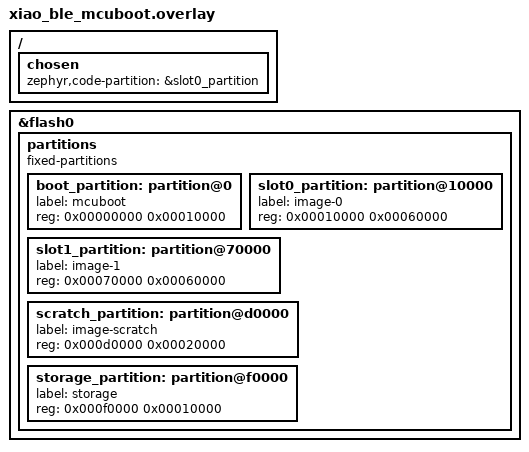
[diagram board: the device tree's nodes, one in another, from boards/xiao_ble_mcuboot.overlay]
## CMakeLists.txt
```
# SPDX-License-Identifier: Apache-2.0

cmake_minimum_required(VERSION 3.20.0)

find_package(Zephyr REQUIRED HINTS $ENV{ZEPHYR_BASE})
project(blinky)

target_sources(app PRIVATE src/main.c)

# Set the signing key for MCUboot
set(mcuboot_key_file "${CMAKE_CURRENT_SOURCE_DIR}/keys/mcuboot-rsa-key.pem")
set_property(GLOBAL PROPERTY PROPERTY_MCUBOOT_SIGNATURE_KEY_FILE "${mcuboot_key_file}")

# Configure OpenOCD runner for west flash
board_runner_args(openocd "--config=openocd-pico-nrf52.cfg")
```

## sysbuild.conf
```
# Sysbuild configuration for MCUboot
SB_CONFIG_BOOTLOADER_MCUBOOT=y
```

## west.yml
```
runner:
  openocd:
    args: ["-f", "openocd-pico-nrf52.cfg"]
```

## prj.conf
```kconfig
# SPDX-License-Identifier: Apache-2.0

# Enable GPIO
CONFIG_GPIO=y

# Enable LED support
CONFIG_LED=y

# Logging configuration
CONFIG_LOG=y
CONFIG_LOG_DEFAULT_LEVEL=3

# USB configuration
CONFIG_USB_DEVICE_STACK=y
CONFIG_USB_DEVICE_PRODUCT="Zephyr Data Streamer"
CONFIG_USB_CDC_ACM=y
CONFIG_USB_DEVICE_INITIALIZE_AT_BOOT=y

# CONFIG_USB_DEVICE_STACK_NEXT=y
# CONFIG_USBD_SHELL=y
# CONFIG_USBH_SHELL=y
# CONFIG_USB_DFU_CLASS=y


CONFIG_USB_DEVICE_STACK=y
#CONFIG_SHELL_BACKEND_USB=y

# Networking support (for external Wi-Fi modules)
CONFIG_NETWORKING=y
CONFIG_NET_TCP=y
CONFIG_NET_UDP=y
CONFIG_NET_IPV4=y
CONFIG_NET_DHCPV4=y
CONFIG_NET_SOCKETS=y
CONFIG_NET_SOCKETS_POSIX_NAMES=y

# MCUboot support for DFU
CONFIG_BOOTLOADER_MCUBOOT=y
CONFIG_MCUBOOT_SIGNATURE_KEY_FILE="keys/mcuboot-rsa-key.pem"
CONFIG_USB_CDC_ACM_LOG_LEVEL_DBG=n

# Console configuration - route to USB
CONFIG_CONSOLE=y
CONFIG_UART_CONSOLE=y

# Shell configuration
CONFIG_SHELL=y
CONFIG_SHELL_BACKEND_SERIAL=y
CONFIG_SHELL_BACKEND_RTT=y
CONFIG_SHELL_PROMPT_UART="usb:~$ "
CONFIG_SHELL_CMDS=y
CONFIG_SHELL_CMDS_RESIZE=y
CONFIG_KERNEL_SHELL=y
CONFIG_DEVICE_SHELL=y
CONFIG_LOG_DEFAULT_LEVEL=3
CONFIG_SHELL_LOG_BACKEND=y

# System reboot support
# CONFIG_REBOOT=y

# Bluetooth LE configuration for data streaming
CONFIG_BT=y
CONFIG_BT_SHELL=y
CONFIG_BT_PERIPHERAL=y
CONFIG_BT_DEVICE_NAME_DYNAMIC=y
CONFIG_BT_DEVICE_NAME="AlexBlue"
CONFIG_BT_DEVICE_APPEARANCE=0
CONFIG_BT_MAX_CONN=1
CONFIG_BT_L2CAP_TX_MTU=247
CONFIG_BT_BUF_ACL_TX_SIZE=251
CONFIG_BT_BUF_ACL_RX_SIZE=251
CONFIG_BT_HCI=y
CONFIG_BT_CTLR=y

# GATT service for custom data streaming
CONFIG_BT_GATT_SERVICE_CHANGED=y
CONFIG_BT_GATT_CACHING=y
```

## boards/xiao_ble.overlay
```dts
/*
 * Copyright (c) 2024
 * SPDX-License-Identifier: Apache-2.0
 */

/ {
	chosen {
		zephyr,code-partition = &slot0_partition;
	};
};

/* Delete the existing partition layout */
/delete-node/ &{/soc/flash-controller@4001e000/flash@0/partitions};

&flash0 {
	partitions {
		compatible = "fixed-partitions";
		#address-cells = <1>;
		#size-cells = <1>;

		/* Reserve space for MCUboot */
		mcuboot_partition: partition@0 {
			label = "mcuboot";
			reg = <0x000000000 0x0000C000>;
		};
		
		/* Main application slot */
		slot0_partition: partition@c000 {
			label = "image-0";
			reg = <0x0000C000 0x00076000>;
		};
		
		/* Update slot for DFU */
		slot1_partition: partition@82000 {
			label = "image-1";
			reg = <0x00082000 0x00076000>;
		};
		
		/* Storage area */
		storage_partition: partition@f8000 {
			label = "storage";
			reg = <0x000f8000 0x00008000>;
		};
	};
};
```

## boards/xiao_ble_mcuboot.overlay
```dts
// MCUboot device tree overlay for nRF52840
/delete-node/ &sd_partition;
/delete-node/ &code_partition;
/delete-node/ &storage_partition;
/delete-node/ &boot_partition;

/ {
	chosen {
		zephyr,code-partition = &slot0_partition;
	};
};

&flash0 {
	partitions {
		compatible = "fixed-partitions";
		#address-cells = <1>;
		#size-cells = <1>;

		boot_partition: partition@0 {
			label = "mcuboot";
			reg = <0x00000000 0x00010000>;
		};
		slot0_partition: partition@10000 {
			label = "image-0";
			reg = <0x00010000 0x00060000>;
		};
		slot1_partition: partition@70000 {
			label = "image-1";
			reg = <0x00070000 0x00060000>;
		};
		scratch_partition: partition@d0000 {
			label = "image-scratch";
			reg = <0x000d0000 0x00020000>;
		};
		storage_partition: partition@f0000 {
			label = "storage";
			reg = <0x000f0000 0x00010000>;
		};
	};
};
```

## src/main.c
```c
/*
 * Copyright (c) 2016 Intel Corporation
 *
 * SPDX-License-Identifier: Apache-2.0
 */

#include <zephyr/kernel.h>
#include <zephyr/drivers/gpio.h>
#include <zephyr/logging/log.h>
#include <zephyr/shell/shell.h>
#include <zephyr/sys/reboot.h>
#include <zephyr/bluetooth/bluetooth.h>
#include <zephyr/bluetooth/gap.h>
#include <zephyr/bluetooth/gatt.h>
#include <zephyr/bluetooth/uuid.h>

LOG_MODULE_REGISTER(main);

/* 1000 msec = 1 sec */
#define SLEEP_TIME_MS   1000

/* The devicetree node identifier for the "led0" alias. */
#define LED0_NODE DT_ALIAS(led0)

/*
 * A build error on this line means your board is unsupported.
 * See the sample documentation for information on how to fix this.
 */
static const struct gpio_dt_spec led = GPIO_DT_SPEC_GET(LED0_NODE, gpios);

/* Bluetooth advertising data */
static const struct bt_data ad[] = {
	BT_DATA_BYTES(BT_DATA_FLAGS, (BT_LE_AD_GENERAL | BT_LE_AD_NO_BREDR)),
	BT_DATA(BT_DATA_NAME_COMPLETE, CONFIG_BT_DEVICE_NAME, sizeof(CONFIG_BT_DEVICE_NAME) - 1),
};

/* Bluetooth scan response data (optional additional info) */
static const struct bt_data sd[] = {
	BT_DATA_BYTES(BT_DATA_UUID16_ALL, BT_UUID_16_ENCODE(BT_UUID_GATT_VAL)),
};

/* Bluetooth ready callback */
static void bt_ready_cb(int err)
{
	if (err) {
		LOG_ERR("Bluetooth init failed (err %d)", err);
		return;
	}

	LOG_INF("Bluetooth initialized");
	printk("Bluetooth initialized successfully\n");

	/* Start advertising */
	err = bt_le_adv_start(BT_LE_ADV_CONN_NAME, ad, ARRAY_SIZE(ad), sd, ARRAY_SIZE(sd));
	if (err) {
		LOG_ERR("Advertising failed to start (err %d)", err);
		printk("ERROR: Failed to start advertising! err = %d\n", err);
		return;
	}

	LOG_INF("Advertising successfully started");
	printk("Bluetooth advertising started as '%s'\n", CONFIG_BT_DEVICE_NAME);
}

/* Shell command to control LED */
static int cmd_led_on(const struct shell *shell, size_t argc, char **argv)
{
	ARG_UNUSED(argc);
	ARG_UNUSED(argv);
	
	gpio_pin_set_dt(&led, 1);
	shell_print(shell, "LED turned ON");
	return 0;
}

static int cmd_led_off(const struct shell *shell, size_t argc, char **argv)
{
	ARG_UNUSED(argc);
	ARG_UNUSED(argv);
	
	gpio_pin_set_dt(&led, 0);
	shell_print(shell, "LED turned OFF");
	return 0;
}

static int cmd_led_toggle(const struct shell *shell, size_t argc, char **argv)
{
	ARG_UNUSED(argc);
	ARG_UNUSED(argv);
	
	gpio_pin_toggle_dt(&led);
	shell_print(shell, "LED toggled");
	return 0;
}

static int cmd_dfu_mode(const struct shell *shell, size_t argc, char **argv)
{
	ARG_UNUSED(argc);
	ARG_UNUSED(argv);
	
	shell_print(shell, "Entering DFU mode...");
	shell_print(shell, "Device will reboot into bootloader for USB flashing");
	k_msleep(100); // Give time for message to be sent
	
	/* Reboot into DFU mode */
	// sys_reboot(SYS_REBOOT_COLD);
	
	return 0;
}

static int cmd_bt_start_adv(const struct shell *shell, size_t argc, char **argv)
{
	ARG_UNUSED(argc);
	ARG_UNUSED(argv);
	
	int err = bt_le_adv_start(BT_LE_ADV_CONN_NAME, ad, ARRAY_SIZE(ad), sd, ARRAY_SIZE(sd));
	if (err) {
		shell_print(shell, "Failed to start advertising (err %d)", err);
	} else {
		shell_print(shell, "Advertising started as '%s'", CONFIG_BT_DEVICE_NAME);
	}
	return 0;
}

static int cmd_bt_stop_adv(const struct shell *shell, size_t argc, char **argv)
{
	ARG_UNUSED(argc);
	ARG_UNUSED(argv);
	
	int err = bt_le_adv_stop();
	if (err) {
		shell_print(shell, "Failed to stop advertising (err %d)", err);
	} else {
		shell_print(shell, "Advertising stopped");
	}
	return 0;
}

SHELL_STATIC_SUBCMD_SET_CREATE(sub_led,
	SHELL_CMD(on, NULL, "Turn LED on", cmd_led_on),
	SHELL_CMD(off, NULL, "Turn LED off", cmd_led_off),
	SHELL_CMD(toggle, NULL, "Toggle LED", cmd_led_toggle),
	SHELL_SUBCMD_SET_END /* Array terminated. */
);

// SHELL_STATIC_SUBCMD_SET_CREATE(sub_bt,
//     SHELL_CMD(start, NULL, "Start advertising", cmd_bt_start_adv),
//     SHELL_CMD(stop, NULL, "Stop advertising", cmd_bt_stop_adv),
//     SHELL_SUBCMD_SET_END /* Array terminated. */
// );

SHELL_CMD_REGISTER(led, &sub_led, "LED commands", NULL);
// SHELL_CMD_REGISTER(bt, &sub_bt, "Bluetooth commands", NULL);
SHELL_CMD_REGISTER(dfu, NULL, "Enter DFU mode for USB flashing", cmd_dfu_mode);

int main(void)
{
	int ret;

	printk("=== nRF52840 Blinky Application Starting ===\n");

	if (!gpio_is_ready_dt(&led)) {
		LOG_ERR("Error: the LED devicetree node is not ready");
		printk("ERROR: LED devicetree node not ready!\n");
		return 0;
	}

	printk("LED GPIO is ready\n");

	ret = gpio_pin_configure_dt(&led, GPIO_OUTPUT_ACTIVE);
	if (ret < 0) {
		LOG_ERR("Error %d: failed to configure the LED pin", ret);
		printk("ERROR: Failed to configure LED pin! ret = %d\n", ret);
		return 0;
	}

	printk("LED pin configured successfully\n");

	/* Initialize Bluetooth */
	ret = bt_enable(bt_ready_cb);
	if (ret) {
		LOG_ERR("Bluetooth init failed (err %d)", ret);
		printk("ERROR: Bluetooth initialization failed! ret = %d\n", ret);
	} else {
		printk("Bluetooth initialization started...\n");
	}

	LOG_INF("LED blink example started");
	printk("Hello from nRF52840! LED blink starting...\n");

	while (1) {
		ret = gpio_pin_toggle_dt(&led);
		if (ret < 0) {
			LOG_ERR("Error %d: failed to toggle LED", ret);
			printk("ERROR: Failed to toggle LED! ret = %d\n", ret);
			return 0;
		}
		
		// LOG_INF("LED toggled");
		// printk("LED toggled\n");
		k_msleep(SLEEP_TIME_MS);
	}
	
	return 0;
}
```
